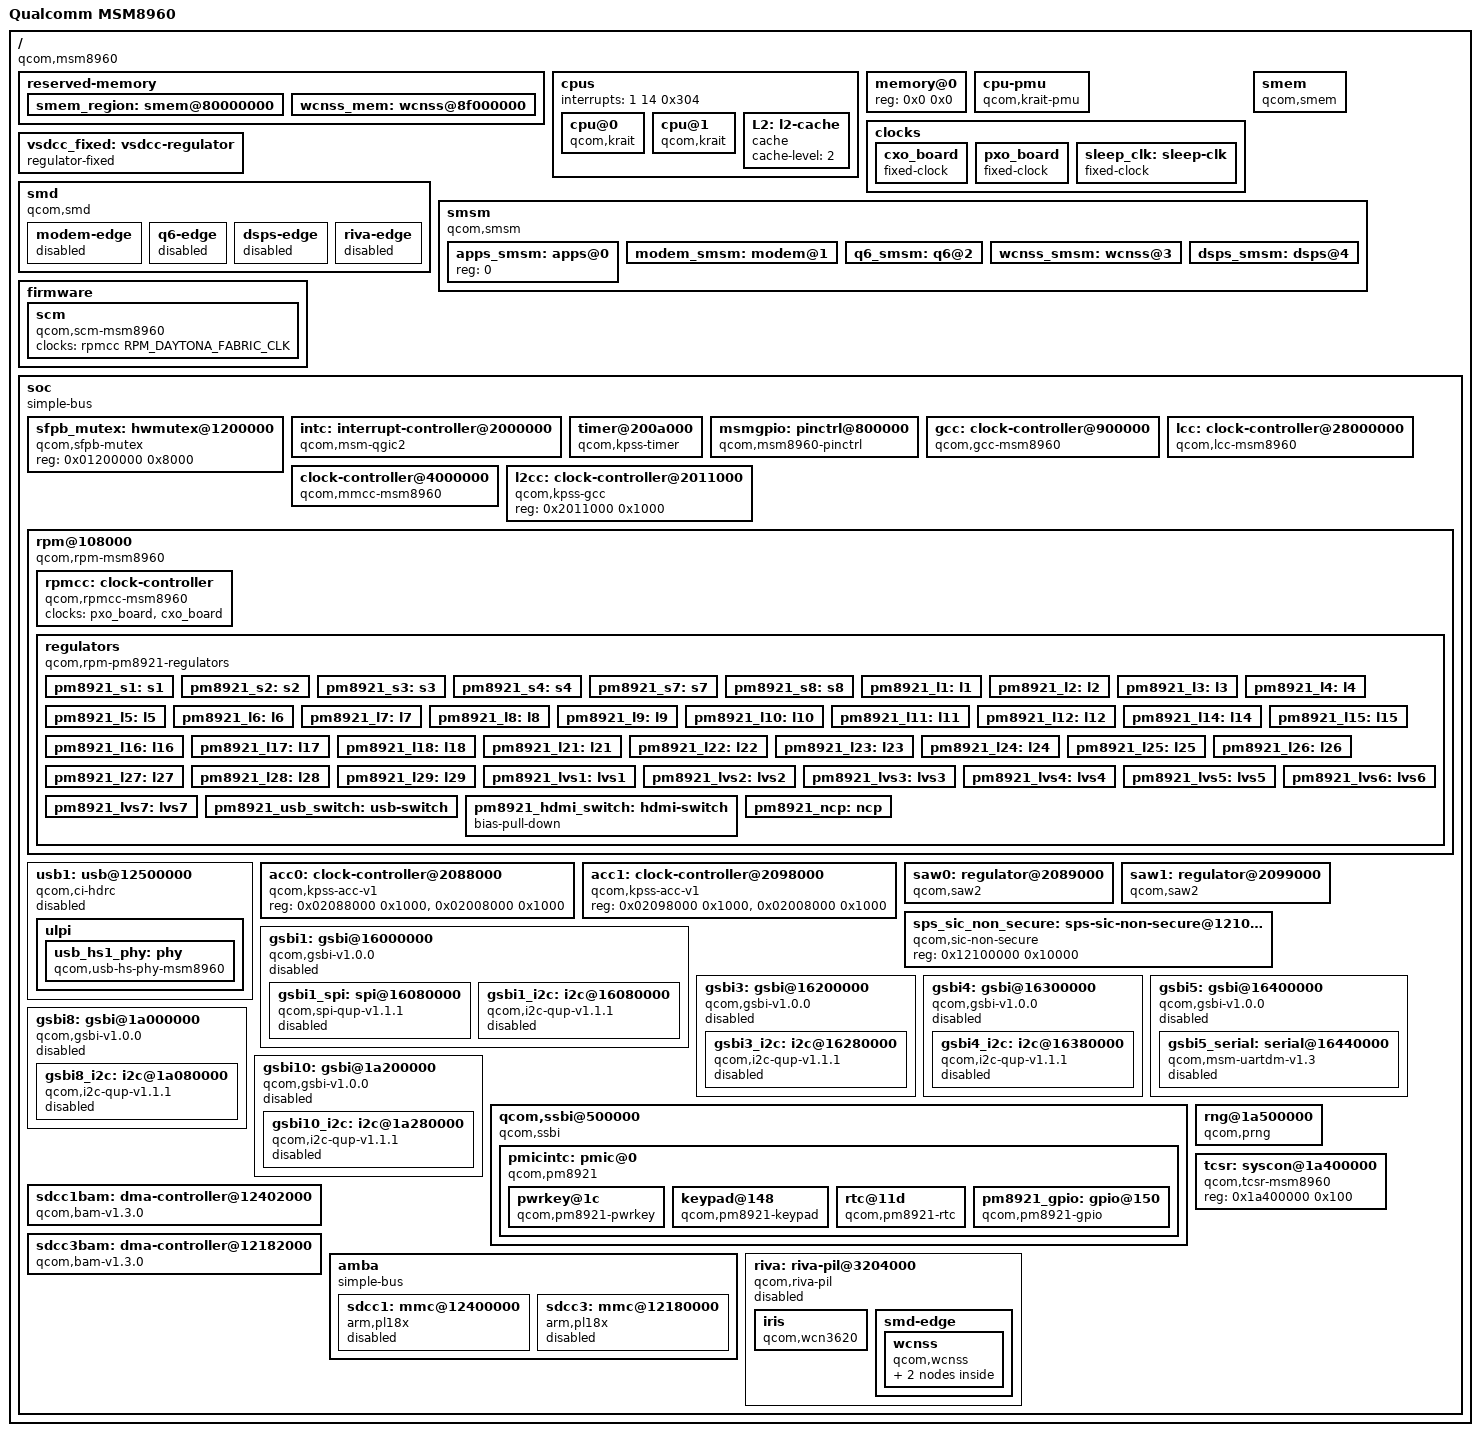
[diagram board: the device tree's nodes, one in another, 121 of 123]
// SPDX-License-Identifier: GPL-2.0
/dts-v1/;

#include <dt-bindings/clock/qcom,gcc-msm8960.h>
#include <dt-bindings/clock/qcom,lcc-msm8960.h>
#include <dt-bindings/reset/qcom,gcc-msm8960.h>
#include <dt-bindings/clock/qcom,rpmcc.h>
#include <dt-bindings/mfd/qcom-rpm.h>
#include <dt-bindings/soc/qcom,gsbi.h>
#include <dt-bindings/interrupt-controller/arm-gic.h>

/ {
	#address-cells = <1>;
	#size-cells = <1>;
	model = "Qualcomm MSM8960";
	compatible = "qcom,msm8960";
	interrupt-parent = <&intc>;

	reserved-memory {
		#address-cells = <1>;
		#size-cells = <1>;
		ranges;

		smem_region: smem@80000000 {
			reg = <0x80000000 0x200000>;
			no-map;
		};

		wcnss_mem: wcnss@8f000000 {
			reg = <0x8f000000 0x700000>;
			no-map;
		};
	};

	cpus {
		#address-cells = <1>;
		#size-cells = <0>;
		interrupts = <1 14 0x304>;

		cpu@0 {
			compatible = "qcom,krait";
			enable-method = "qcom,kpss-acc-v1";
			device_type = "cpu";
			reg = <0>;
			next-level-cache = <&L2>;
			qcom,acc = <&acc0>;
			qcom,saw = <&saw0>;
		};

		cpu@1 {
			compatible = "qcom,krait";
			enable-method = "qcom,kpss-acc-v1";
			device_type = "cpu";
			reg = <1>;
			next-level-cache = <&L2>;
			qcom,acc = <&acc1>;
			qcom,saw = <&saw1>;
		};

		L2: l2-cache {
			compatible = "cache";
			cache-level = <2>;
		};
	};

	memory@0 {
		device_type = "memory";
		reg = <0x0 0x0>;
	};

	cpu-pmu {
		compatible = "qcom,krait-pmu";
		interrupts = <1 10 0x304>;
		qcom,no-pc-write;
	};

	clocks {
		cxo_board: cxo_board {
			compatible = "fixed-clock";
			#clock-cells = <0>;
			clock-frequency = <19200000>;
			clock-output-names = "cxo_board";
		};

		pxo_board: pxo_board {
			compatible = "fixed-clock";
			#clock-cells = <0>;
			clock-frequency = <27000000>;
			clock-output-names = "pxo_board";
		};

		sleep_clk: sleep-clk {
			compatible = "fixed-clock";
			#clock-cells = <0>;
			clock-frequency = <32768>;
			clock-output-names = "sleep_clk";
		};
	};

	/* Temporary fixed regulator */
	vsdcc_fixed: vsdcc-regulator {
		compatible = "regulator-fixed";
		regulator-name = "SDCC Power";
		regulator-min-microvolt = <2700000>;
		regulator-max-microvolt = <2700000>;
		regulator-always-on;
	};

	smem {
		compatible = "qcom,smem";
		memory-region = <&smem_region>;

		hwlocks = <&sfpb_mutex 3>;
	};

	smd {
		compatible = "qcom,smd";

		modem-edge {
			interrupts = <GIC_SPI 37 IRQ_TYPE_EDGE_RISING>;

			qcom,ipc = <&l2cc 8 3>;
			qcom,smd-edge = <0>;

			status = "disabled";
		};

		q6-edge {
			interrupts = <GIC_SPI 90 IRQ_TYPE_EDGE_RISING>;

			qcom,ipc = <&l2cc 8 15>;
			qcom,smd-edge = <1>;

			status = "disabled";
		};

		dsps-edge {
			interrupts = <GIC_SPI 138 IRQ_TYPE_EDGE_RISING>;

			qcom,ipc = <&sps_sic_non_secure 0x4080 0>;
			qcom,smd-edge = <3>;

			status = "disabled";
		};

		riva-edge {
			interrupts = <GIC_SPI 198 IRQ_TYPE_EDGE_RISING>;

			qcom,ipc = <&l2cc 8 25>;
			qcom,smd-edge = <6>;

			status = "disabled";
		};
	};

	smsm {
		compatible = "qcom,smsm";

		#address-cells = <1>;
		#size-cells = <0>;

		qcom,ipc-1 = <&l2cc 8 4>;
		qcom,ipc-2 = <&l2cc 8 14>;
		qcom,ipc-3 = <&l2cc 8 23>;
		qcom,ipc-4 = <&sps_sic_non_secure 0x4094 0>;

		apps_smsm: apps@0 {
			reg = <0>;
			#qcom,smem-state-cells = <1>;
		};

		modem_smsm: modem@1 {
			reg = <1>;
			interrupts = <GIC_SPI 38 IRQ_TYPE_EDGE_RISING>;

			interrupt-controller;
			#interrupt-cells = <2>;
		};

		q6_smsm: q6@2 {
			reg = <2>;
			interrupts = <GIC_SPI 89 IRQ_TYPE_EDGE_RISING>;

			interrupt-controller;
			#interrupt-cells = <2>;
		};

		wcnss_smsm: wcnss@3 {
			reg = <3>;
			interrupts = <GIC_SPI 204 IRQ_TYPE_EDGE_RISING>;

			interrupt-controller;
			#interrupt-cells = <2>;
		};

		dsps_smsm: dsps@4 {
			reg = <4>;
			interrupts = <GIC_SPI 137 IRQ_TYPE_EDGE_RISING>;

			interrupt-controller;
			#interrupt-cells = <2>;
		};
	};

	firmware {
		scm {
			compatible = "qcom,scm-msm8960", "qcom,scm";

			clocks = <&rpmcc RPM_DAYTONA_FABRIC_CLK>;
			clock-names = "core";
		};
	};

	soc: soc {
		#address-cells = <1>;
		#size-cells = <1>;
		ranges;
		compatible = "simple-bus";

		sfpb_mutex: hwmutex@1200000 {
			compatible = "qcom,sfpb-mutex";
			reg = <0x01200000 0x8000>;
			#hwlock-cells = <1>;
		};

		intc: interrupt-controller@2000000 {
			compatible = "qcom,msm-qgic2";
			interrupt-controller;
			#interrupt-cells = <3>;
			reg = <0x02000000 0x1000>,
			      <0x02002000 0x1000>;
		};

		timer@200a000 {
			compatible = "qcom,kpss-timer",
				     "qcom,kpss-wdt-msm8960", "qcom,msm-timer";
			interrupts = <1 1 0x301>,
				     <1 2 0x301>,
				     <1 3 0x301>;
			reg = <0x0200a000 0x100>;
			clock-frequency = <27000000>;
			cpu-offset = <0x80000>;
		};

		msmgpio: pinctrl@800000 {
			compatible = "qcom,msm8960-pinctrl";
			gpio-controller;
			gpio-ranges = <&msmgpio 0 0 152>;
			#gpio-cells = <2>;
			interrupts = <0 16 0x4>;
			interrupt-controller;
			#interrupt-cells = <2>;
			reg = <0x800000 0x4000>;
		};

		gcc: clock-controller@900000 {
			compatible = "qcom,gcc-msm8960";
			#clock-cells = <1>;
			#power-domain-cells = <1>;
			#reset-cells = <1>;
			reg = <0x900000 0x4000>;
			clocks = <&cxo_board>,
				 <&pxo_board>,
				 <&lcc PLL4>;
			clock-names = "cxo", "pxo", "pll4";
		};

		lcc: clock-controller@28000000 {
			compatible = "qcom,lcc-msm8960";
			reg = <0x28000000 0x1000>;
			#clock-cells = <1>;
			#reset-cells = <1>;
			clocks = <&pxo_board>,
				 <&gcc PLL4_VOTE>,
				 <0>,
				 <0>, <0>,
				 <0>, <0>,
				 <0>;
			clock-names = "pxo",
				      "pll4_vote",
				      "mi2s_codec_clk",
				      "codec_i2s_mic_codec_clk",
				      "spare_i2s_mic_codec_clk",
				      "codec_i2s_spkr_codec_clk",
				      "spare_i2s_spkr_codec_clk",
				      "pcm_codec_clk";
		};

		clock-controller@4000000 {
			compatible = "qcom,mmcc-msm8960";
			reg = <0x4000000 0x1000>;
			#clock-cells = <1>;
			#power-domain-cells = <1>;
			#reset-cells = <1>;
			clocks = <&pxo_board>,
				 <&gcc PLL3>,
				 <&gcc PLL8_VOTE>,
				 <0>,
				 <0>,
				 <0>,
				 <0>,
				 <0>;
			clock-names = "pxo",
				      "pll3",
				      "pll8_vote",
				      "dsi1pll",
				      "dsi1pllbyte",
				      "dsi2pll",
				      "dsi2pllbyte",
				      "hdmipll";
		};

		l2cc: clock-controller@2011000 {
			compatible = "qcom,kpss-gcc", "syscon";
			reg = <0x2011000 0x1000>;
		};

		rpm@108000 {
			compatible = "qcom,rpm-msm8960";
			reg = <0x108000 0x1000>;
			qcom,ipc = <&l2cc 0x8 2>;

			interrupts = <GIC_SPI 19 IRQ_TYPE_EDGE_RISING>,
				     <GIC_SPI 21 IRQ_TYPE_EDGE_RISING>,
				     <GIC_SPI 22 IRQ_TYPE_EDGE_RISING>;
			interrupt-names = "ack", "err", "wakeup";

			rpmcc: clock-controller {
				compatible = "qcom,rpmcc-msm8960", "qcom,rpmcc";
				#clock-cells = <1>;
				clocks = <&pxo_board>, <&cxo_board>;
				clock-names = "pxo", "cxo";
			};

			regulators {
				compatible = "qcom,rpm-pm8921-regulators";

				pm8921_s1: s1 {};
				pm8921_s2: s2 {};
				pm8921_s3: s3 {};
				pm8921_s4: s4 {};
				pm8921_s7: s7 {};
				pm8921_s8: s8 {};

				pm8921_l1: l1 {};
				pm8921_l2: l2 {};
				pm8921_l3: l3 {};
				pm8921_l4: l4 {};
				pm8921_l5: l5 {};
				pm8921_l6: l6 {};
				pm8921_l7: l7 {};
				pm8921_l8: l8 {};
				pm8921_l9: l9 {};
				pm8921_l10: l10 {};
				pm8921_l11: l11 {};
				pm8921_l12: l12 {};
				pm8921_l14: l14 {};
				pm8921_l15: l15 {};
				pm8921_l16: l16 {};
				pm8921_l17: l17 {};
				pm8921_l18: l18 {};
				pm8921_l21: l21 {};
				pm8921_l22: l22 {};
				pm8921_l23: l23 {};
				pm8921_l24: l24 {};
				pm8921_l25: l25 {};
				pm8921_l26: l26 {};
				pm8921_l27: l27 {};
				pm8921_l28: l28 {};
				pm8921_l29: l29 {};

				pm8921_lvs1: lvs1 {};
				pm8921_lvs2: lvs2 {};
				pm8921_lvs3: lvs3 {};
				pm8921_lvs4: lvs4 {};
				pm8921_lvs5: lvs5 {};
				pm8921_lvs6: lvs6 {};
				pm8921_lvs7: lvs7 {};

				pm8921_usb_switch: usb-switch {};

				pm8921_hdmi_switch: hdmi-switch {
					bias-pull-down;
				};

				pm8921_ncp: ncp {};
			};
		};

		usb1: usb@12500000 {
			compatible = "qcom,ci-hdrc";
			reg = <0x12500000 0x200>,
			      <0x12500200 0x200>;
			interrupts = <GIC_SPI 100 IRQ_TYPE_LEVEL_HIGH>;
			clocks = <&gcc USB_HS1_XCVR_CLK>, <&gcc USB_HS1_H_CLK>;
			clock-names = "core", "iface";
			assigned-clocks = <&gcc USB_HS1_XCVR_CLK>;
			assigned-clock-rates = <60000000>;
			resets = <&gcc USB_HS1_RESET>;
			reset-names = "core";
			phy_type = "ulpi";
			ahb-burst-config = <0>;
			phys = <&usb_hs1_phy>;
			phy-names = "usb-phy";
			#reset-cells = <1>;
			status = "disabled";

			ulpi {
				usb_hs1_phy: phy {
					compatible = "qcom,usb-hs-phy-msm8960",
						     "qcom,usb-hs-phy";
					clocks = <&sleep_clk>, <&cxo_board>;
					clock-names = "sleep", "ref";
					resets = <&usb1 0>;
					reset-names = "por";
					#phy-cells = <0>;
				};
			};
		};

		acc0: clock-controller@2088000 {
			compatible = "qcom,kpss-acc-v1";
			reg = <0x02088000 0x1000>, <0x02008000 0x1000>;
		};

		acc1: clock-controller@2098000 {
			compatible = "qcom,kpss-acc-v1";
			reg = <0x02098000 0x1000>, <0x02008000 0x1000>;
		};

		saw0: regulator@2089000 {
			compatible = "qcom,saw2";
			reg = <0x02089000 0x1000>, <0x02009000 0x1000>;
			regulator;
		};

		saw1: regulator@2099000 {
			compatible = "qcom,saw2";
			reg = <0x02099000 0x1000>, <0x02009000 0x1000>;
			regulator;
		};

		sps_sic_non_secure: sps-sic-non-secure@12100000 {
			compatible = "qcom,sic-non-secure", "syscon";
			reg = <0x12100000 0x10000>;
		};

		gsbi1: gsbi@16000000 {
			compatible = "qcom,gsbi-v1.0.0";
			cell-index = <1>;
			reg = <0x16000000 0x100>;
			clocks = <&gcc GSBI1_H_CLK>;
			clock-names = "iface";
			#address-cells = <1>;
			#size-cells = <1>;
			ranges;

			syscon-tcsr = <&tcsr>;
			status = "disabled";

			gsbi1_spi: spi@16080000 {
				compatible = "qcom,spi-qup-v1.1.1";
				#address-cells = <1>;
				#size-cells = <0>;
				reg = <0x16080000 0x1000>;
				interrupts = <GIC_SPI 147 IRQ_TYPE_LEVEL_HIGH>;
				spi-max-frequency = <24000000>;
				cs-gpios = <&msmgpio 8 0>;

				clocks = <&gcc GSBI1_QUP_CLK>, <&gcc GSBI1_H_CLK>;
				clock-names = "core", "iface";
				status = "disabled";
			};

			gsbi1_i2c: i2c@16080000 {
				compatible = "qcom,i2c-qup-v1.1.1";
				reg = <0x16080000 0x1000>;
				interrupts = <GIC_SPI 147 IRQ_TYPE_LEVEL_HIGH>;
				clocks = <&gcc GSBI1_QUP_CLK>, <&gcc GSBI1_H_CLK>;
				clock-names = "core", "iface";
				#address-cells = <1>;
				#size-cells = <0>;
				status = "disabled";
			};

		};

		gsbi3: gsbi@16200000 {
			compatible = "qcom,gsbi-v1.0.0";
			cell-index = <3>;
			reg = <0x16200000 0x100>;
			clocks = <&gcc GSBI3_H_CLK>;
			clock-names = "iface";
			#address-cells = <1>;
			#size-cells = <1>;
			ranges;

			syscon-tcsr = <&tcsr>;
			status = "disabled";

			gsbi3_i2c: i2c@16280000 {
				compatible = "qcom,i2c-qup-v1.1.1";
				reg = <0x16280000 0x1000>;
				interrupts = <GIC_SPI 151 IRQ_TYPE_LEVEL_HIGH>;
				clocks = <&gcc GSBI3_QUP_CLK>, <&gcc GSBI3_H_CLK>;
				clock-names = "core", "iface";
				#address-cells = <1>;
				#size-cells = <0>;
				status = "disabled";
			};
		};

		gsbi4: gsbi@16300000 {
			compatible = "qcom,gsbi-v1.0.0";
			cell-index = <4>;
			reg = <0x16300000 0x100>;
			clocks = <&gcc GSBI4_H_CLK>;
			clock-names = "iface";
			#address-cells = <1>;
			#size-cells = <1>;
			ranges;

			syscon-tcsr = <&tcsr>;
			status = "disabled";

			gsbi4_i2c: i2c@16380000 {
				compatible = "qcom,i2c-qup-v1.1.1";
				reg = <0x16380000 0x1000>;
				interrupts = <GIC_SPI 153 IRQ_TYPE_LEVEL_HIGH>;
				clocks = <&gcc GSBI4_QUP_CLK>, <&gcc GSBI4_H_CLK>;
				clock-names = "core", "iface";
				#address-cells = <1>;
				#size-cells = <0>;
				status = "disabled";
			};
		};

		gsbi5: gsbi@16400000 {
			compatible = "qcom,gsbi-v1.0.0";
			cell-index = <5>;
			reg = <0x16400000 0x100>;
			clocks = <&gcc GSBI5_H_CLK>;
			clock-names = "iface";
			#address-cells = <1>;
			#size-cells = <1>;
			ranges;

			syscon-tcsr = <&tcsr>;
			status = "disabled";

			gsbi5_serial: serial@16440000 {
				compatible = "qcom,msm-uartdm-v1.3", "qcom,msm-uartdm";
				reg = <0x16440000 0x1000>,
				      <0x16400000 0x1000>;
				interrupts = <GIC_SPI 154 IRQ_TYPE_LEVEL_HIGH>;
				clocks = <&gcc GSBI5_UART_CLK>, <&gcc GSBI5_H_CLK>;
				clock-names = "core", "iface";
				status = "disabled";
			};
		};

		gsbi8: gsbi@1a000000 {
			compatible = "qcom,gsbi-v1.0.0";
			cell-index = <8>;
			reg = <0x1a000000 0x100>;
			clocks = <&gcc GSBI8_H_CLK>;
			clock-names = "iface";
			#address-cells = <1>;
			#size-cells = <1>;
			ranges;

			syscon-tcsr = <&tcsr>;
			status = "disabled";

			gsbi8_i2c: i2c@1a080000 {
				compatible = "qcom,i2c-qup-v1.1.1";
				reg = <0x1a080000 0x1000>;
				interrupts = <GIC_SPI 161 IRQ_TYPE_LEVEL_HIGH>;
				clocks = <&gcc GSBI8_QUP_CLK>, <&gcc GSBI8_H_CLK>;
				clock-names = "core", "iface";
				#address-cells = <1>;
				#size-cells = <0>;
				status = "disabled";
			};
		};

		gsbi10: gsbi@1a200000 {
			compatible = "qcom,gsbi-v1.0.0";
			cell-index = <10>;
			reg = <0x1a200000 0x100>;
			clocks = <&gcc GSBI10_H_CLK>;
			clock-names = "iface";
			#address-cells = <1>;
			#size-cells = <1>;
			ranges;

			syscon-tcsr = <&tcsr>;
			status = "disabled";

			gsbi10_i2c: i2c@1a280000 {
				compatible = "qcom,i2c-qup-v1.1.1";
				reg = <0x1a280000 0x1000>;
				interrupts = <GIC_SPI 192 IRQ_TYPE_LEVEL_HIGH>;
				clocks = <&gcc GSBI10_QUP_CLK>, <&gcc GSBI10_H_CLK>;
				clock-names = "core", "iface";
				#address-cells = <1>;
				#size-cells = <0>;
				status = "disabled";
			};
		};

		qcom,ssbi@500000 {
			compatible = "qcom,ssbi";
			reg = <0x500000 0x1000>;
			qcom,controller-type = "pmic-arbiter";

			pmicintc: pmic@0 {
				compatible = "qcom,pm8921";
				interrupt-parent = <&msmgpio>;
				interrupts = <104 8>;
				#interrupt-cells = <2>;
				interrupt-controller;
				#address-cells = <1>;
				#size-cells = <0>;

				pwrkey@1c {
					compatible = "qcom,pm8921-pwrkey";
					reg = <0x1c>;
					interrupt-parent = <&pmicintc>;
					interrupts = <50 1>, <51 1>;
					debounce = <15625>;
					pull-up;
				};

				keypad@148 {
					compatible = "qcom,pm8921-keypad";
					reg = <0x148>;
					interrupt-parent = <&pmicintc>;
					interrupts = <74 1>, <75 1>;
					debounce = <15>;
					scan-delay = <32>;
					row-hold = <91500>;
				};

				rtc@11d {
					compatible = "qcom,pm8921-rtc";
					interrupt-parent = <&pmicintc>;
					interrupts = <39 1>;
					reg = <0x11d>;
					allow-set-time;
				};

				pm8921_gpio: gpio@150 {
					compatible = "qcom,pm8921-gpio", "qcom,ssbi-gpio";
					reg = <0x150>;
					interrupt-controller;
					#interrupt-cells = <2>;
					gpio-controller;
					gpio-ranges = <&pm8921_gpio 0 0 44>;
					#gpio-cells = <2>;
				};
			};
		};

		rng@1a500000 {
			compatible = "qcom,prng";
			reg = <0x1a500000 0x200>;
			clocks = <&gcc PRNG_CLK>;
			clock-names = "core";
		};

		sdcc1bam: dma-controller@12402000{
			compatible = "qcom,bam-v1.3.0";
			reg = <0x12402000 0x8000>;
			interrupts = <GIC_SPI 98 IRQ_TYPE_LEVEL_HIGH>;
			clocks = <&gcc SDC1_H_CLK>;
			clock-names = "bam_clk";
			#dma-cells = <1>;
			qcom,ee = <0>;
		};

		sdcc3bam: dma-controller@12182000{
			compatible = "qcom,bam-v1.3.0";
			reg = <0x12182000 0x8000>;
			interrupts = <GIC_SPI 96 IRQ_TYPE_LEVEL_HIGH>;
			clocks = <&gcc SDC3_H_CLK>;
			clock-names = "bam_clk";
			#dma-cells = <1>;
			qcom,ee = <0>;
		};

		amba {
			compatible = "simple-bus";
			#address-cells = <1>;
			#size-cells = <1>;
			ranges;
			sdcc1: mmc@12400000 {
				status = "disabled";
				compatible = "arm,pl18x", "arm,primecell";
				arm,primecell-periphid = <0x00051180>;
				reg = <0x12400000 0x2000>;
				interrupts = <GIC_SPI 104 IRQ_TYPE_LEVEL_HIGH>;
				interrupt-names = "cmd_irq";
				clocks = <&gcc SDC1_CLK>, <&gcc SDC1_H_CLK>;
				clock-names = "mclk", "apb_pclk";
				bus-width = <8>;
				max-frequency = <96000000>;
				non-removable;
				cap-sd-highspeed;
				cap-mmc-highspeed;
				dmas = <&sdcc1bam 2>, <&sdcc1bam 1>;
				dma-names = "tx", "rx";
			};

			sdcc3: mmc@12180000 {
				compatible = "arm,pl18x", "arm,primecell";
				arm,primecell-periphid = <0x00051180>;
				status = "disabled";
				reg = <0x12180000 0x2000>;
				interrupts = <GIC_SPI 102 IRQ_TYPE_LEVEL_HIGH>;
				interrupt-names = "cmd_irq";
				clocks = <&gcc SDC3_CLK>, <&gcc SDC3_H_CLK>;
				clock-names = "mclk", "apb_pclk";
				bus-width = <4>;
				cap-sd-highspeed;
				cap-mmc-highspeed;
				max-frequency = <192000000>;
				no-1-8-v;
				dmas = <&sdcc3bam 2>, <&sdcc3bam 1>;
				dma-names = "tx", "rx";
			};
		};

		tcsr: syscon@1a400000 {
			compatible = "qcom,tcsr-msm8960", "syscon";
			reg = <0x1a400000 0x100>;
		};

		riva: riva-pil@3204000 {
			compatible = "qcom,riva-pil";

			reg = <0x03200800 0x1000>, <0x03202000 0x2000>, <0x03204000 0x100>;
			reg-names = "ccu", "dxe", "pmu";

			interrupts-extended = <&intc GIC_SPI 199 IRQ_TYPE_EDGE_RISING>,
					      <&wcnss_smsm 6 IRQ_TYPE_EDGE_RISING>,
					      <&wcnss_smsm 7 IRQ_TYPE_EDGE_RISING>,
					      <&wcnss_smsm 8 IRQ_TYPE_EDGE_RISING>,
					      <&wcnss_smsm 9 IRQ_TYPE_EDGE_RISING>;
			interrupt-names = "wdog", "fatal", "ready", "handover", "stop-ack";

			memory-region = <&wcnss_mem>;

			vddcx-supply = <&pm8921_s3>;
			vddmx-supply = <&pm8921_l24>;
			vddpx-supply = <&pm8921_s4>;

			status = "disabled";

			iris {
				compatible = "qcom,wcn3620";

				clocks = <&cxo_board>;
				clock-names = "xo";

				vddxo-supply = <&pm8921_l4>;
				vddrfa-supply = <&pm8921_s2>;
				vddpa-supply = <&pm8921_l10>;
				vdddig-supply = <&pm8921_lvs2>;
			};

			smd-edge {
				interrupts = <GIC_SPI 198 IRQ_TYPE_EDGE_RISING>;

				qcom,ipc = <&l2cc 8 25>;
				qcom,smd-edge = <6>;

				label = "riva";

				wcnss {
					compatible = "qcom,wcnss";
					qcom,smd-channels = "WCNSS_CTRL";

					qcom,mmio = <&riva>;

					bluetooth {
						compatible = "qcom,wcnss-bt";
					};

					wifi {
						compatible = "qcom,wcnss-wlan";

						interrupts = <GIC_SPI 203 IRQ_TYPE_LEVEL_HIGH>,
							     <GIC_SPI 202 IRQ_TYPE_LEVEL_HIGH>;
						interrupt-names = "tx", "rx";

						qcom,smem-states = <&apps_smsm 10>, <&apps_smsm 9>;
						qcom,smem-state-names = "tx-enable", "tx-rings-empty";
						local-mac-address = [ 18 00 2d 88 9c a9 ];
					};
				};
			};
		};
	};
};
